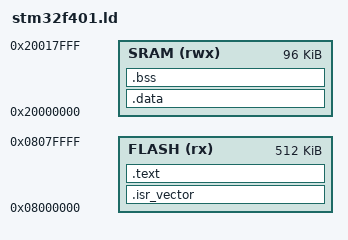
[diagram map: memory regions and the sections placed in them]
/* STM32F401RE memory map */
MEMORY
{
  FLASH (rx)  : ORIGIN = 0x08000000, LENGTH = 512K
  SRAM  (rwx) : ORIGIN = 0x20000000, LENGTH = 96K
}

_estack = ORIGIN(SRAM) + LENGTH(SRAM);

SECTIONS
{
  .isr_vector :
  {
    KEEP(*(.isr_vector))
  } > FLASH

  .text :
  {
    *(.text*)
    *(.rodata*)
    _etext = .;
  } > FLASH

  _sidata = LOADADDR(.data);
  .data : AT(_etext)
  {
    _sdata = .;
    *(.data*)
    _edata = .;
  } > SRAM

  .bss (NOLOAD) :
  {
    _sbss = .;
    *(.bss*)
    *(COMMON)
    _ebss = .;
  } > SRAM
}

